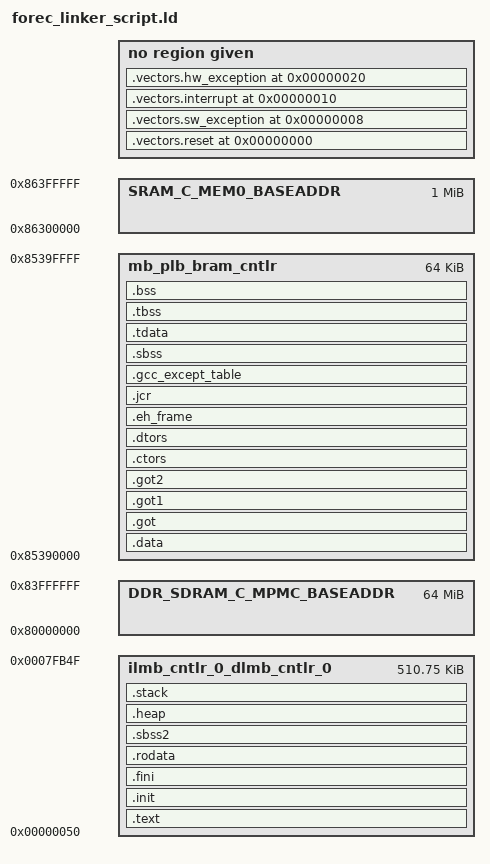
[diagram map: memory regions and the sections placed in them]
/*******************************************************************/
/*                                                                 */
/* This file is automatically generated by linker script generator.*/
/*                                                                 */
/* Version: Xilinx EDK 12.4 EDK_MS4.81d                            */
/*                                                                 */
/* Copyright (c) 2009 Xilinx, Inc.  All rights reserved.           */
/*                                                                 */
/* Description : MicroBlaze Linker Script                          */
/*                                                                 */
/*******************************************************************/

_STACK_SIZE = DEFINED(_STACK_SIZE) ? _STACK_SIZE : 0x2000;
_HEAP_SIZE = DEFINED(_HEAP_SIZE) ? _HEAP_SIZE : 0x2000;

/* Define Memories in the system */

MEMORY
{
   ilmb_cntlr_0_dlmb_cntlr_0 : ORIGIN = 0x00000050, LENGTH = 0x0007FB00
   DDR_SDRAM_C_MPMC_BASEADDR : ORIGIN = 0x80000000, LENGTH = 0x04000000
   mb_plb_bram_cntlr : ORIGIN = 0x85390000, LENGTH = 0x00010000
   SRAM_C_MEM0_BASEADDR : ORIGIN = 0x86300000, LENGTH = 0x00100000
}

/* Specify the default entry point to the program */

ENTRY(_start)

/* Define the sections, and where they are mapped in memory */

SECTIONS
{
.vectors.reset 0x00000000 : {
   *(.vectors.reset)
} 

.vectors.sw_exception 0x00000008 : {
   *(.vectors.sw_exception)
} 

.vectors.interrupt 0x00000010 : {
   *(.vectors.interrupt)
} 

.vectors.hw_exception 0x00000020 : {
   *(.vectors.hw_exception)
} 

.text : {
   *(.text)
   *(.text.*)
   *(.gnu.linkonce.t.*)
} > ilmb_cntlr_0_dlmb_cntlr_0

.init : {
   KEEP (*(.init))
} > ilmb_cntlr_0_dlmb_cntlr_0

.fini : {
   KEEP (*(.fini))
} > ilmb_cntlr_0_dlmb_cntlr_0

.rodata : {
   __rodata_start = .;
   *(.rodata)
   *(.rodata.*)
   *(.gnu.linkonce.r.*)
   __rodata_end = .;
} > ilmb_cntlr_0_dlmb_cntlr_0

.sbss2 : {
   __sbss2_start = .;
   *(.sbss2)
   *(.sbss2.*)
   *(.gnu.linkonce.sb2.*)
   __sbss2_end = .;
} > ilmb_cntlr_0_dlmb_cntlr_0

.data : {
   . = ALIGN(4);
   __data_start = .;
   *(.data)
   *(.data.*)
   *(.gnu.linkonce.d.*)
   __data_end = .;
} > mb_plb_bram_cntlr

.got : {
   *(.got)
} > mb_plb_bram_cntlr

.got1 : {
   *(.got1)
} > mb_plb_bram_cntlr

.got2 : {
   *(.got2)
} > mb_plb_bram_cntlr

.ctors : {
   __CTOR_LIST__ = .;
   ___CTORS_LIST___ = .;
   KEEP (*crtbegin.o(.ctors))
   KEEP (*(EXCLUDE_FILE(*crtend.o) .ctors))
   KEEP (*(SORT(.ctors.*)))
   KEEP (*(.ctors))
   __CTOR_END__ = .;
   ___CTORS_END___ = .;
} > mb_plb_bram_cntlr

.dtors : {
   __DTOR_LIST__ = .;
   ___DTORS_LIST___ = .;
   KEEP (*crtbegin.o(.dtors))
   KEEP (*(EXCLUDE_FILE(*crtend.o) .dtors))
   KEEP (*(SORT(.dtors.*)))
   KEEP (*(.dtors))
   __DTOR_END__ = .;
   ___DTORS_END___ = .;
} > mb_plb_bram_cntlr

.eh_frame : {
   *(.eh_frame)
} > mb_plb_bram_cntlr

.jcr : {
   *(.jcr)
} > mb_plb_bram_cntlr

.gcc_except_table : {
   *(.gcc_except_table)
} > mb_plb_bram_cntlr

.sbss : {
   . = ALIGN(4);
   __sbss_start = .;
   *(.sbss)
   *(.sbss.*)
   *(.gnu.linkonce.sb.*)
   . = ALIGN(8);
   __sbss_end = .;
} > mb_plb_bram_cntlr

.tdata : {
   __tdata_start = .;
   *(.tdata)
   *(.tdata.*)
   *(.gnu.linkonce.td.*)
   __tdata_end = .;
} > mb_plb_bram_cntlr

.tbss : {
   __tbss_start = .;
   *(.tbss)
   *(.tbss.*)
   *(.gnu.linkonce.tb.*)
   __tbss_end = .;
} > mb_plb_bram_cntlr

.bss : {
   . = ALIGN(4);
   __bss_start = .;
   *(.bss)
   *(.bss.*)
   *(.gnu.linkonce.b.*)
   *(COMMON)
   . = ALIGN(4);
   __bss_end = .;
} > mb_plb_bram_cntlr

_SDA_BASE_ = ((__sbss_end - __sbss_start) / 2 );

_SDA2_BASE_ = ((__sbss2_end - __sbss2_start) / 2 );

/* Generate Stack and Heap definitions */

.heap : {
   . = ALIGN(8);
   _heap = .;
   _heap_start = .;
   . += _HEAP_SIZE;
   _heap_end = .;
} > ilmb_cntlr_0_dlmb_cntlr_0

.stack : {
   _stack_end = .;
   . += _STACK_SIZE;
   . = ALIGN(8);
   _stack = .;
   __stack = _stack;
} > ilmb_cntlr_0_dlmb_cntlr_0

}

